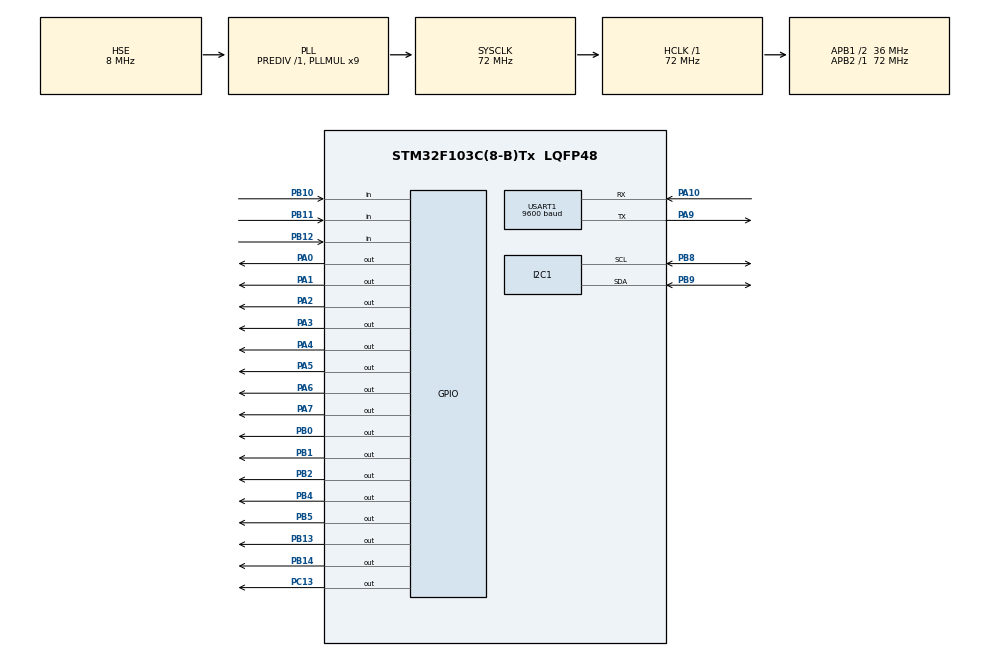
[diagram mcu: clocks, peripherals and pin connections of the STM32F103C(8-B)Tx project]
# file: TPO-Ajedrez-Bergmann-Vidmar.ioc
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Mcu.Family=STM32F1
Mcu.Name=STM32F103C(8-B)Tx
Mcu.Package=LQFP48
NVIC.PriorityGroup=NVIC_PRIORITYGROUP_4
NVIC.TIM2_IRQn=true\:0\:0\:false\:false\:true\:true\:true\:true
NVIC.TIM3_IRQn=true\:0\:0\:false\:false\:true\:true\:true\:true
NVIC.TIM4_IRQn=true\:0\:0\:false\:false\:true\:true\:true\:true
NVIC.USART1_IRQn=true\:0\:0\:false\:false\:true\:true\:true\:true
PA0-WKUP.Signal=GPIO_Output
PA1.Signal=GPIO_Output
PA10.Mode=Asynchronous
PA10.Signal=USART1_RX
PA13.Mode=Serial_Wire
PA13.Signal=SYS_JTMS-SWDIO
PA14.Mode=Serial_Wire
PA14.Signal=SYS_JTCK-SWCLK
PA2.Signal=GPIO_Output
PA3.Signal=GPIO_Output
PA4.Signal=GPIO_Output
PA5.Signal=GPIO_Output
PA6.Signal=GPIO_Output
PA7.Signal=GPIO_Output
PA9.Mode=Asynchronous
PA9.Signal=USART1_TX
PB0.Signal=GPIO_Output
PB1.Signal=GPIO_Output
PB10.GPIO_PuPd=GPIO_PULLUP
PB10.Signal=GPIO_Input
PB11.GPIO_PuPd=GPIO_PULLUP
PB11.Signal=GPIO_Input
PB12.GPIO_PuPd=GPIO_PULLUP
PB12.Signal=GPIO_Input
PB13.Signal=GPIO_Output
PB14.Signal=GPIO_Output
PB2.Signal=GPIO_Output
PB4.Signal=GPIO_Output
PB5.Signal=GPIO_Output
PB8.Mode=I2C
PB8.Signal=I2C1_SCL
PB9.Mode=I2C
PB9.Signal=I2C1_SDA
PC13-TAMPER-RTC.Signal=GPIO_Output
PD0-OSC_IN.Mode=HSE-External-Oscillator
PD0-OSC_IN.Signal=RCC_OSC_IN
PD1-OSC_OUT.Mode=HSE-External-Oscillator
PD1-OSC_OUT.Signal=RCC_OSC_OUT
ProjectManager.HeapSize=0x200
ProjectManager.StackSize=0x400
ProjectManager.TargetToolchain=STM32CubeIDE
RCC.ADCPresc=RCC_ADCPCLK2_DIV6
RCC.AHBFreq_Value=72000000
RCC.APB1CLKDivider=RCC_HCLK_DIV2
RCC.APB1Freq_Value=36000000
RCC.APB1TimFreq_Value=72000000
RCC.APB2Freq_Value=72000000
RCC.APB2TimFreq_Value=72000000
RCC.HCLKFreq_Value=72000000
RCC.PLLMUL=RCC_PLL_MUL9
RCC.PLLSourceVirtual=RCC_PLLSOURCE_HSE
RCC.SYSCLKFreq_VALUE=72000000
RCC.SYSCLKSource=RCC_SYSCLKSOURCE_PLLCLK
RCC.USBFreq_Value=72000000
TIM1.Period=144-1
TIM1.Prescaler=1000-1
TIM2.Period=7200
TIM2.Prescaler=1000
TIM3.Period=72-1
TIM3.Prescaler=1000-1
USART1.BaudRate=9600
USART1.VirtualMode=VM_ASYNC
VP_TIM1_VS_ClockSourceINT.Mode=Internal
VP_TIM2_VS_ClockSourceINT.Mode=Internal
VP_TIM3_VS_ClockSourceINT.Mode=Internal
VP_TIM4_VS_ClockSourceINT.Mode=Internal
board=custom

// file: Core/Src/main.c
#include "main.h"

void SystemClock_Config(void);

int main(void)
{

  /* Reset of all peripherals, Initializes the Flash interface and the Systick. */
  HAL_Init();

  HAL_Delay(5000); //let debugger catch up

  /* Configure the system clock */
  SystemClock_Config();

  /* Initialize all configured peripherals */
  MX_GPIO_Init();
  MX_TIM2_Init();
  MX_TIM3_Init();
  MX_USART1_UART_Init();
  MX_I2C1_Init();
  MX_TIM1_Init();
  MX_TIM4_Init();
  lcd_init();
  lcd_clear();

  /* Show end of init */
  lcd_change_text("Initializing...");
  usart_print("\n\rInitializing...\n\r");

  // Initialize FSM (this must be the last one to init)
  fsm_init();

  /* Start timers */
  HAL_TIM_Base_Start_IT(&htim1);
  HAL_TIM_Base_Start_IT(&htim3);

  /* Move to origin */
  lcd_change_text("Origin...");
  usart_print("\n\rMoving to origin...\n\r");
  volverOrigen();

  while (1)
  {
    DebounceEntradas();
    stepperWatchDog();
    if (!rutinaOrigin) // If not in origin rutine, run FSM
      fsm();
  }

}

void SystemClock_Config(void)
{
  RCC_OscInitTypeDef RCC_OscInitStruct = {0};
  RCC_ClkInitTypeDef RCC_ClkInitStruct = {0};

  /** Initializes the RCC Oscillators according to the specified parameters
  * in the RCC_OscInitTypeDef structure.
  */
  RCC_OscInitStruct.OscillatorType = RCC_OSCILLATORTYPE_HSE;
  RCC_OscInitStruct.HSEState = RCC_HSE_ON;
  RCC_OscInitStruct.HSEPredivValue = RCC_HSE_PREDIV_DIV1;
  RCC_OscInitStruct.HSIState = RCC_HSI_ON;
  RCC_OscInitStruct.PLL.PLLState = RCC_PLL_ON;
  RCC_OscInitStruct.PLL.PLLSource = RCC_PLLSOURCE_HSE;
  RCC_OscInitStruct.PLL.PLLMUL = RCC_PLL_MUL9;
  if (HAL_RCC_OscConfig(&RCC_OscInitStruct) != HAL_OK)
  {
    Error_Handler();
  }

  /** Initializes the CPU, AHB and APB buses clocks
  */
  RCC_ClkInitStruct.ClockType = RCC_CLOCKTYPE_HCLK|RCC_CLOCKTYPE_SYSCLK
                              |RCC_CLOCKTYPE_PCLK1|RCC_CLOCKTYPE_PCLK2;
  RCC_ClkInitStruct.SYSCLKSource = RCC_SYSCLKSOURCE_PLLCLK;
  RCC_ClkInitStruct.AHBCLKDivider = RCC_SYSCLK_DIV1;
  RCC_ClkInitStruct.APB1CLKDivider = RCC_HCLK_DIV2;
  RCC_ClkInitStruct.APB2CLKDivider = RCC_HCLK_DIV1;

  if (HAL_RCC_ClockConfig(&RCC_ClkInitStruct, FLASH_LATENCY_2) != HAL_OK)
  {
    Error_Handler();
  }
}

void Error_Handler(void)
{
  /* USER CODE BEGIN Error_Handler_Debug */
  /* User can add his own implementation to report the HAL error return state */
  __disable_irq();
  while (1)
  {
    usart_print("\n\rError_Handler...\n\r");
  }
  /* USER CODE END Error_Handler_Debug */
}
